VERSION ""

NS_ :

BS_:

BU_: Engine Transmission PumpControl Display

BO_ 402653552 MSG1: 8 Engine
 SG_ EngineSpeed : 0|16@1+ (1,0) [0|0] "" Vector__XXX
 SG_ ScaledDischargePressure : 16|16@1+ (1,-5000) [0|15000] "psi" Vector__XXX
 SG_ Rate : 32|16@1+ (0.1,0) [0|0] "" Vector__XXX
 SG_ TotalBBL : 48|16@1+ (1,0) [0|0] "" Vector__XXX
 SG_ SIGNAL4012Engine_SPeeed : 0|16@1+ (1,0) [0|0] "" Vector__XXX

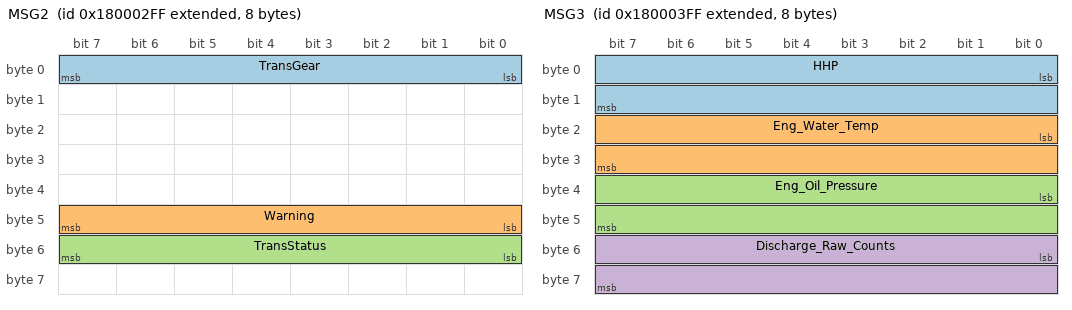
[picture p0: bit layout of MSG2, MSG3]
BO_ 2550137599 MSG2: 8 Transmission
 SG_ TransGear : 0|8@1+ (1,0) [0|0] "" Vector__XXX
 SG_ Warning : 40|8@1+ (1,0) [0|0] "" Vector__XXX
 SG_ TransStatus : 48|8@1+ (1,0) [0|0] "" Vector__XXX

BO_ 2550137855 MSG3: 8 Engine
 SG_ HHP : 0|16@1+ (1,0) [0|0] "" Vector__XXX
 SG_ Eng_Water_Temp : 16|16@1+ (1,0) [0|0] "" Vector__XXX
 SG_ Eng_Oil_Pressure : 32|16@1+ (0.1,-750) [0|0] "psi" Vector__XXX
 SG_ Discharge_Raw_Counts : 48|16@1+ (1,-750) [0|0] "" Vector__XXX

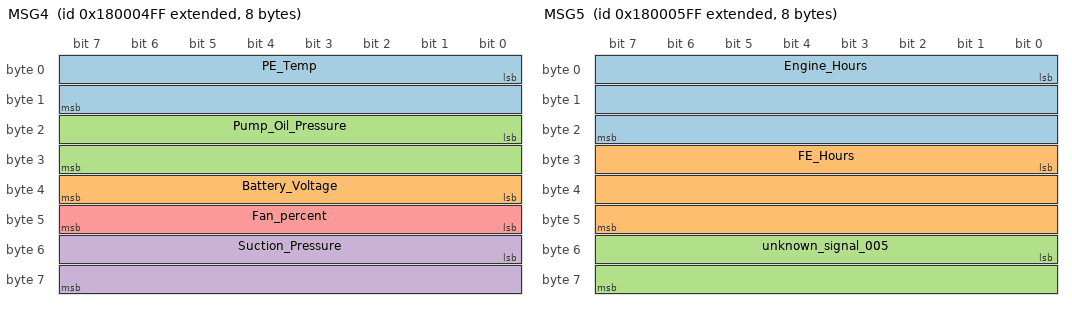
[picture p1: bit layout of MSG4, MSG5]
BO_ 2550138111 MSG4: 8 PumpControl
 SG_ PE_Temp : 0|16@1+ (1,-100) [0|0] "F" Vector__XXX
 SG_ Battery_Voltage : 32|8@1+ (0.1,0) [0|0] "volts" Vector__XXX
 SG_ Pump_Oil_Pressure : 16|16@1+ (0.1,-750) [0|0] "" Vector__XXX
 SG_ Suction_Pressure : 48|16@1+ (0.1,-1000) [0|0] "psi" Vector__XXX
 SG_ Fan_percent : 40|8@1+ (1,0) [0|0] "" Vector__XXX

BO_ 2550138367 MSG5: 8 PumpControl
 SG_ Engine_Hours : 0|24@1+ (0.1,0) [0|0] "hours" Vector__XXX
 SG_ FE_Hours : 24|24@1+ (0.1,0) [0|0] "" Vector__XXX
 SG_ unknown_signal_005 : 48|16@1+ (1,0) [0|0] "" Vector__XXX

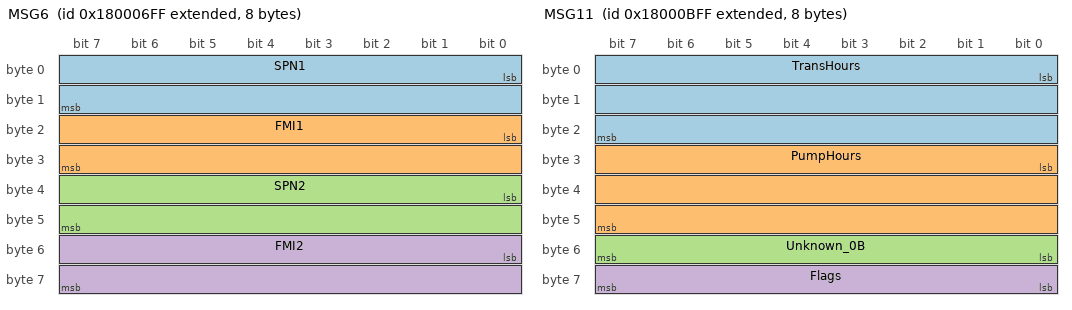
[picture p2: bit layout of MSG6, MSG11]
BO_ 2550138623 MSG6: 8 Engine
 SG_ SPN1 : 0|16@1+ (1,0) [0|0] "" Vector__XXX
 SG_ FMI1 : 16|16@1+ (1,0) [0|0] "" Vector__XXX
 SG_ SPN2 : 32|16@1+ (1,0) [0|0] "" Vector__XXX
 SG_ FMI2 : 48|16@1+ (1,0) [0|0] "" Vector__XXX

BO_ 2550139647 MSG10: 8 PumpControl
 SG_ Disch_Pressure : 0|16@1+ (1,-5000) [0|0] "psi" Vector__XXX
 SG_ Total_Strokes : 32|32@1+ (1,0) [0|0] "" Vector__XXX

BO_ 2550139903 MSG11: 8 PumpControl
 SG_ TransHours : 0|24@1+ (0.1,0) [0|0] "" Vector__XXX
 SG_ PumpHours : 24|24@1+ (0.1,0) [0|0] "" Vector__XXX
 SG_ Unknown_0B : 48|8@1+ (1,0) [0|0] "" Vector__XXX
 SG_ Flags : 56|8@1+ (1,0) [0|0] "" Vector__XXX

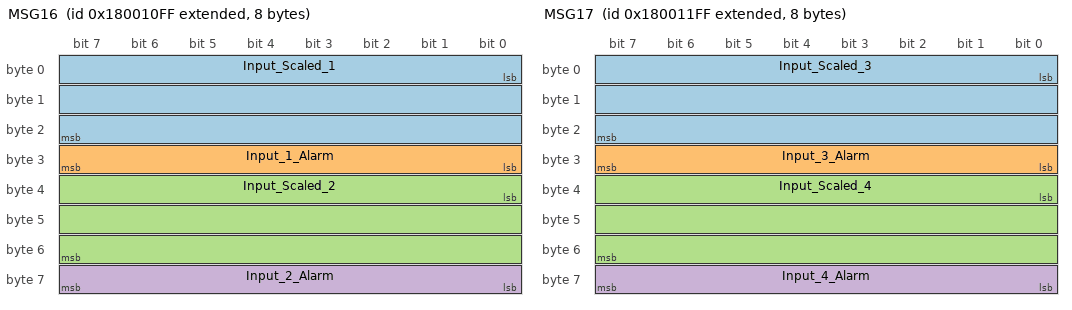
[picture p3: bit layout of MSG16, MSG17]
BO_ 2550141183 MSG16: 8 PumpControl
 SG_ Input_Scaled_1 : 0|24@1+ (0.01,-500000) [0|0] "" Vector__XXX
 SG_ Input_1_Alarm : 24|8@1+ (1,0) [0|0] "" Vector__XXX
 SG_ Input_Scaled_2 : 32|24@1+ (0.01,-500000) [0|0] "" Vector__XXX
 SG_ Input_2_Alarm : 56|8@1+ (1,0) [0|0] "" Vector__XXX

BO_ 2550141439 MSG17: 8 PumpControl
 SG_ Input_Scaled_3 : 0|24@1+ (0.01,-500000) [0|0] "" Vector__XXX
 SG_ Input_3_Alarm : 24|8@1+ (1,0) [0|0] "" Vector__XXX
 SG_ Input_Scaled_4 : 32|24@1+ (0.01,-500000) [0|0] "" Vector__XXX
 SG_ Input_4_Alarm : 56|8@1+ (1,0) [0|0] "" Vector__XXX

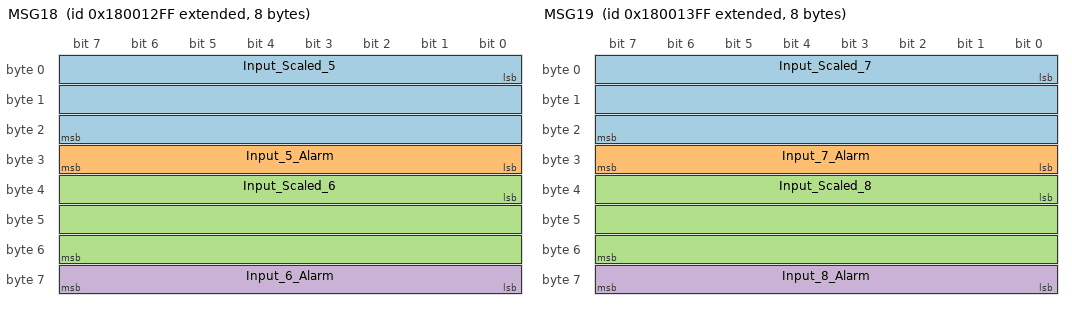
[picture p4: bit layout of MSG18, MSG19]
BO_ 2550141695 MSG18: 8 PumpControl
 SG_ Input_Scaled_5 : 0|24@1+ (0.01,-500000) [0|0] "" Vector__XXX
 SG_ Input_5_Alarm : 24|8@1+ (1,0) [0|0] "" Vector__XXX
 SG_ Input_Scaled_6 : 32|24@1+ (0.01,-500000) [0|0] "" Vector__XXX
 SG_ Input_6_Alarm : 56|8@1+ (1,0) [0|0] "" Vector__XXX

BO_ 2550141951 MSG19: 8 PumpControl
 SG_ Input_Scaled_7 : 0|24@1+ (0.01,-500000) [0|0] "" Vector__XXX
 SG_ Input_7_Alarm : 24|8@1+ (1,0) [0|0] "" Vector__XXX
 SG_ Input_Scaled_8 : 32|24@1+ (0.01,-500000) [0|0] "" Vector__XXX
 SG_ Input_8_Alarm : 56|8@1+ (1,0) [0|0] "" Vector__XXX

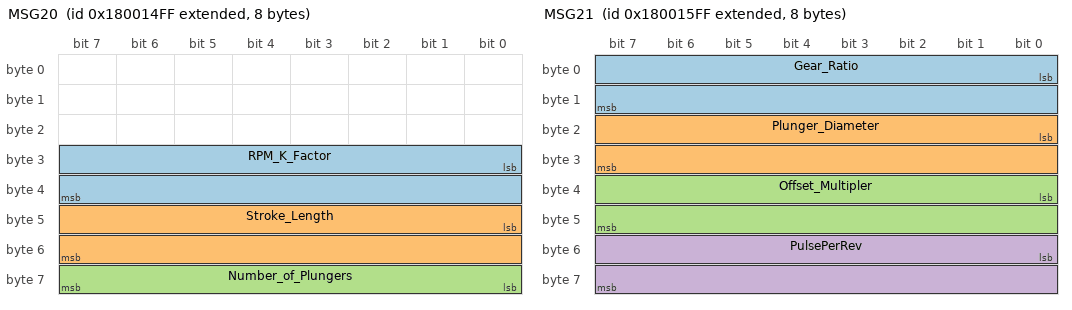
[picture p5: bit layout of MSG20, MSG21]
BO_ 2550142207 MSG20: 8 Display
 SG_ RPM_K_Factor : 24|16@1+ (1,0) [0|0] "" Vector__XXX
 SG_ Stroke_Length : 40|16@1+ (0.1,0) [0|0] "" Vector__XXX
 SG_ Number_of_Plungers : 56|8@1+ (1,0) [0|0] "" Vector__XXX

BO_ 2550142463 MSG21: 8 Display
 SG_ Gear_Ratio : 0|16@1+ (0.01,0) [0|0] "" Vector__XXX
 SG_ Plunger_Diameter : 16|16@1+ (0.01,0) [0|0] "" Vector__XXX
 SG_ Offset_Multipler : 32|16@1+ (0.01,0) [0|0] "" Vector__XXX
 SG_ PulsePerRev : 48|16@1+ (1,0) [0|0] "" Vector__XXX

BO_ 2550142719 MSG22: 8 Display
 SG_ Disch_Raw_Low : 0|16@1+ (1,0) [0|0] "" Vector__XXX
 SG_ Disch_Raw_High : 16|16@1+ (1,0) [0|0] "" Vector__XXX

BO_ 2550142975 MSG23: 8 Display
 SG_ UnitID : 0|48@1+ (1,0) [0|0] "" Vector__XXX
 SG_ OPSD_Set_Point : 48|16@1+ (1,0) [0|0] "" Vector__XXX

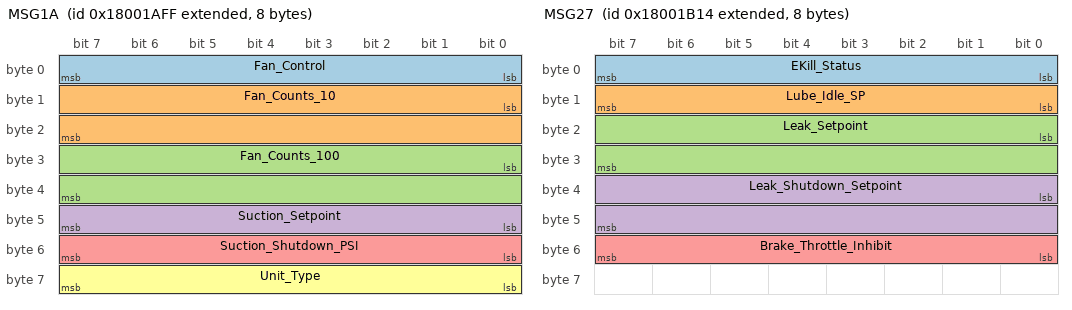
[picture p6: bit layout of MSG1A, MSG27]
BO_ 2550143743 MSG1A: 8 PumpControl
 SG_ Fan_Control : 0|8@1+ (1,0) [0|0] "" Vector__XXX
 SG_ Fan_Counts_10 : 8|16@1+ (1,0) [0|0] "" Vector__XXX
 SG_ Fan_Counts_100 : 24|16@1+ (1,0) [0|0] "" Vector__XXX
 SG_ Suction_Setpoint : 40|8@1+ (1,0) [0|0] "" Vector__XXX
 SG_ Suction_Shutdown_PSI : 48|8@1+ (1,0) [0|0] "psi" Vector__XXX
 SG_ Unit_Type : 56|8@1+ (1,0) [0|0] "" Vector__XXX

BO_ 2550143764 MSG27: 8 PumpControl
 SG_ EKill_Status : 0|8@1+ (1,0) [0|0] "" Vector__XXX
 SG_ Lube_Idle_SP : 8|8@1+ (1,0) [0|0] "" Vector__XXX
 SG_ Leak_Setpoint : 16|16@1+ (1,0) [0|0] "" Vector__XXX
 SG_ Leak_Shutdown_Setpoint : 32|16@1+ (1,0) [0|0] "" Vector__XXX
 SG_ Brake_Throttle_Inhibit : 48|8@1+ (1,0) [0|0] "" Vector__XXX
